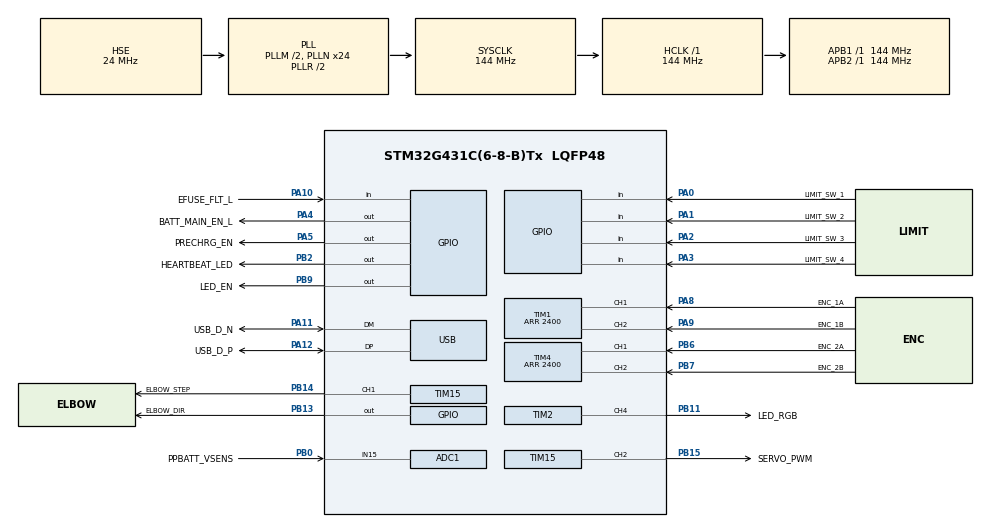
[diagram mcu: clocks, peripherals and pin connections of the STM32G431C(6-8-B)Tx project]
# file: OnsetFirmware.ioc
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ADC1.Channel-5\#ChannelRegularConversion=ADC_CHANNEL_15
ADC1.Channel-IN15=ADC_CHANNEL_15
ADC1.ClockPrescaler=ADC_CLOCK_SYNC_PCLK_DIV4
ADC1.ContinuousConvMode=DISABLE
ADC1.DMAContinuousRequests=DISABLE
ADC1.DataAlign=ADC_DATAALIGN_RIGHT
ADC1.DiscontinuousConvMode=DISABLE
ADC1.EOCSelection=ADC_EOC_SINGLE_CONV
ADC1.EnableAnalogWatchDog1=false
ADC1.EnableAnalogWatchDog2=false
ADC1.EnableAnalogWatchDog3=false
ADC1.EnableInjectedConversion=DISABLE
ADC1.EnableRegularConversion=ENABLE
ADC1.ExternalTrigConv=ADC_SOFTWARE_START
ADC1.ExternalTrigConvEdge=ADC_EXTERNALTRIGCONVEDGE_NONE
ADC1.GainCompensation=0
ADC1.LowPowerAutoWait=DISABLE
ADC1.Mode=ADC_MODE_INDEPENDENT
ADC1.NbrOfConversion=1
ADC1.OffsetNumber-5\#ChannelRegularConversion=ADC_OFFSET_NONE
ADC1.Overrun=ADC_OVR_DATA_PRESERVED
ADC1.OversamplingMode=DISABLE
ADC1.Rank-5\#ChannelRegularConversion=1
ADC1.Resolution=ADC_RESOLUTION_12B
ADC1.SamplingTime-5\#ChannelRegularConversion=ADC_SAMPLETIME_2CYCLES_5
ADC1.ScanConvMode=ADC_SCAN_DISABLE
ADC1.master=1
Dma.Request0=TIM2_CH4
Dma.TIM2_CH4.0.Direction=DMA_MEMORY_TO_PERIPH
Dma.TIM2_CH4.0.EventEnable=DISABLE
Dma.TIM2_CH4.0.Instance=DMA1_Channel1
Dma.TIM2_CH4.0.MemDataAlignment=DMA_MDATAALIGN_WORD
Dma.TIM2_CH4.0.MemInc=DMA_MINC_ENABLE
Dma.TIM2_CH4.0.Mode=DMA_NORMAL
Dma.TIM2_CH4.0.PeriphDataAlignment=DMA_PDATAALIGN_WORD
Dma.TIM2_CH4.0.PeriphInc=DMA_PINC_DISABLE
Dma.TIM2_CH4.0.Polarity=HAL_DMAMUX_REQ_GEN_RISING
Dma.TIM2_CH4.0.Priority=DMA_PRIORITY_LOW
Dma.TIM2_CH4.0.RequestNumber=1
Dma.TIM2_CH4.0.SignalID=NONE
Dma.TIM2_CH4.0.SyncEnable=DISABLE
Dma.TIM2_CH4.0.SyncPolarity=HAL_DMAMUX_SYNC_NO_EVENT
Dma.TIM2_CH4.0.SyncRequestNumber=1
Dma.TIM2_CH4.0.SyncSignalID=NONE
FREERTOS.HEAP_NUMBER=4
FREERTOS.INCLUDE_eTaskGetState=1
FREERTOS.INCLUDE_pcTaskGetTaskName=0
FREERTOS.INCLUDE_uxTaskGetStackHighWaterMark=1
FREERTOS.INCLUDE_uxTaskGetStackHighWaterMark2=0
FREERTOS.INCLUDE_uxTaskPriorityGet=1
FREERTOS.INCLUDE_vTaskCleanUpResources=0
FREERTOS.INCLUDE_vTaskDelay=1
FREERTOS.INCLUDE_vTaskDelayUntil=1
FREERTOS.INCLUDE_vTaskDelete=1
FREERTOS.INCLUDE_vTaskPrioritySet=1
FREERTOS.INCLUDE_vTaskSuspend=1
FREERTOS.INCLUDE_xEventGroupSetBitFromISR=0
FREERTOS.INCLUDE_xQueueGetMutexHolder=1
FREERTOS.INCLUDE_xSemaphoreGetMutexHolder=0
FREERTOS.INCLUDE_xTaskAbortDelay=0
FREERTOS.INCLUDE_xTaskGetCurrentTaskHandle=1
FREERTOS.INCLUDE_xTaskGetHandle=0
FREERTOS.INCLUDE_xTaskGetSchedulerState=1
FREERTOS.INCLUDE_xTaskResumeFromISR=1
FREERTOS.INCLUDE_xTimerPendFunctionCall=1
FREERTOS.Queues01=serial_to_elbow,16,serial_to_elbow_msg_t,0,Dynamic,NULL,NULL;elbow_to_serial,16,elbow_to_serial_msg_t,0,Dynamic,NULL,NULL;serial_to_precharge,16,serial_to_precharge_msg_t,0,Dynamic,NULL,NULL;precharge_to_serial,16,precharge_to_serial_msg_t,0,Dynamic,NULL,NULL;precharge_to_led,16,precharge_to_led_msg_t,0,Dynamic,NULL,NULL;serial_to_led,16,serial_to_led_msg_t,0,Dynamic,NULL,NULL;led_to_serial,16,led_to_serial_msg_t,0,Dynamic,NULL,NULL;serial_to_loader,16,serial_to_loader_msg_t,0,Dynamic,NULL,NULL;loader_to_serial,16,loader_to_serial_msg_t,0,Dynamic,NULL,NULL
FREERTOS.Tasks01=default_task,24,128,start_default_task,Default,NULL,Dynamic,NULL,NULL;elbow_service,24,256,start_elbow_service,As external,NULL,Dynamic,NULL,NULL;heartbeat_service,24,64,start_heartbeat_service,As external,NULL,Dynamic,NULL,NULL;serial_service,24,512,start_serial_service,As external,NULL,Dynamic,NULL,NULL;precharge_service,24,128,start_precharge_service,As external,NULL,Dynamic,NULL,NULL;led_service,24,128,start_led_service,As external,NULL,Dynamic,NULL,NULL;loader_servce,24,64,start_loader_service,As external,NULL,Dynamic,NULL,NULL
FREERTOS.configCHECK_FOR_STACK_OVERFLOW=0
FREERTOS.configENABLE_BACKWARD_COMPATIBILITY=1
FREERTOS.configENABLE_FPU=0
FREERTOS.configGENERATE_RUN_TIME_STATS=0
FREERTOS.configIDLE_SHOULD_YIELD=1
FREERTOS.configLIBRARY_LOWEST_INTERRUPT_PRIORITY=15
FREERTOS.configLIBRARY_MAX_SYSCALL_INTERRUPT_PRIORITY=5
FREERTOS.configMAX_CO_ROUTINE_PRIORITIES=2
FREERTOS.configMAX_TASK_NAME_LEN=32
FREERTOS.configMINIMAL_STACK_SIZE=64
FREERTOS.configQUEUE_REGISTRY_SIZE=8
FREERTOS.configRECORD_STACK_HIGH_ADDRESS=0
FREERTOS.configTICK_RATE_HZ=1000
FREERTOS.configTIMER_QUEUE_LENGTH=10
FREERTOS.configTIMER_TASK_PRIORITY=2
FREERTOS.configTIMER_TASK_STACK_DEPTH=256
FREERTOS.configTOTAL_HEAP_SIZE=8192
FREERTOS.configUSE_APPLICATION_TASK_TAG=0
FREERTOS.configUSE_COUNTING_SEMAPHORES=1
FREERTOS.configUSE_CO_ROUTINES=0
FREERTOS.configUSE_DAEMON_TASK_STARTUP_HOOK=0
FREERTOS.configUSE_IDLE_HOOK=0
FREERTOS.configUSE_MALLOC_FAILED_HOOK=0
FREERTOS.configUSE_MINI_LIST_ITEM=1
FREERTOS.configUSE_MUTEXES=1
FREERTOS.configUSE_NEWLIB_REENTRANT=0
FREERTOS.configUSE_OS2_EVENTFLAGS_FROM_ISR=1
FREERTOS.configUSE_OS2_MUTEX=1
FREERTOS.configUSE_OS2_THREAD_ENUMERATE=1
FREERTOS.configUSE_OS2_THREAD_FLAGS=1
FREERTOS.configUSE_OS2_THREAD_SUSPEND_RESUME=1
FREERTOS.configUSE_OS2_TIMER=1
FREERTOS.configUSE_POSIX_ERRNO=0
FREERTOS.configUSE_PREEMPTION=1
FREERTOS.configUSE_RECURSIVE_MUTEXES=1
FREERTOS.configUSE_SB_COMPLETED_CALLBACK=0
FREERTOS.configUSE_STATS_FORMATTING_FUNCTIONS=0
FREERTOS.configUSE_TASK_NOTIFICATIONS=1
FREERTOS.configUSE_TICKLESS_IDLE=0
FREERTOS.configUSE_TICK_HOOK=0
FREERTOS.configUSE_TRACE_FACILITY=1
FREERTOS.copyHeapFile=1
Mcu.Family=STM32G4
Mcu.Name=STM32G431C(6-8-B)Tx
Mcu.Package=LQFP48
NVIC.DMA1_Channel1_IRQn=true\:5\:0\:true\:false\:true\:true\:false\:true\:true
NVIC.PriorityGroup=NVIC_PRIORITYGROUP_4
NVIC.TIM1_BRK_TIM15_IRQn=true\:5\:0\:true\:false\:true\:true\:true\:true\:true
NVIC.TIM3_IRQn=true\:5\:0\:true\:false\:true\:true\:true\:true\:true
NVIC.TIM6_DAC_IRQn=true\:15\:0\:false\:false\:true\:false\:true\:true\:true
NVIC.TimeBase=TIM6_DAC_IRQn
NVIC.TimeBaseIP=TIM6
NVIC.USB_LP_IRQn=true\:5\:0\:true\:false\:true\:true\:true\:true\:true
PA0.GPIO_Label=LIMIT_SW_1
PA0.GPIO_PuPd=GPIO_PULLUP
PA0.Signal=GPIO_Input
PA1.GPIO_Label=LIMIT_SW_2
PA1.GPIO_PuPd=GPIO_PULLUP
PA1.Signal=GPIO_Input
PA10.GPIO_Label=EFUSE_FLT_L
PA10.Signal=GPIO_Input
PA11.GPIO_Label=USB_D_N
PA11.Mode=Device
PA11.Signal=USB_DM
PA12.GPIO_Label=USB_D_P
PA12.Mode=Device
PA12.Signal=USB_DP
PA13.GPIO_Label=DEBUG_SWDIO
PA13.Mode=Trace_Asynchronous_SW
PA13.Signal=SYS_JTMS-SWDIO
PA14.GPIO_Label=DEBUG_SWCLK
PA14.Mode=Trace_Asynchronous_SW
PA14.Signal=SYS_JTCK-SWCLK
PA2.GPIO_Label=LIMIT_SW_3
PA2.GPIO_PuPd=GPIO_PULLUP
PA2.Signal=GPIO_Input
PA3.GPIO_Label=LIMIT_SW_4
PA3.GPIO_PuPd=GPIO_PULLUP
PA3.Signal=GPIO_Input
PA4.GPIO_Label=BATT_MAIN_EN_L
PA4.PinState=GPIO_PIN_SET
PA4.Signal=GPIO_Output
PA5.GPIO_Label=PRECHRG_EN
PA5.PinState=GPIO_PIN_SET
PA5.Signal=GPIO_Output
PA8.GPIO_Label=ENC_1A
PA8.GPIO_PuPd=GPIO_PULLUP
PA8.Signal=S_TIM1_CH1
PA9.GPIO_Label=ENC_1B
PA9.GPIO_PuPd=GPIO_PULLUP
PA9.Signal=S_TIM1_CH2
PB0.GPIO_Label=PPBATT_VSENS
PB0.Mode=IN15-Single-Ended
PB0.Signal=ADC1_IN15
PB11.GPIO_Label=LED_RGB
PB11.Signal=S_TIM2_CH4
PB13.GPIO_Label=ELBOW_DIR
PB13.Signal=GPIO_Output
PB14.GPIO_Label=ELBOW_STEP
PB14.Signal=S_TIM15_CH1
PB15.GPIO_Label=SERVO_PWM
PB15.Signal=S_TIM15_CH2
PB2.GPIO_Label=HEARTBEAT_LED
PB2.Signal=GPIO_Output
PB3.GPIO_Label=DEBUG_SWO
PB3.Mode=Trace_Asynchronous_SW
PB3.Signal=SYS_JTDO-SWO
PB6.GPIO_Label=ENC_2A
PB6.GPIO_PuPd=GPIO_PULLUP
PB6.Signal=S_TIM4_CH1
PB7.GPIO_Label=ENC_2B
PB7.GPIO_PuPd=GPIO_PULLUP
PB7.Signal=S_TIM4_CH2
PB9.GPIO_Label=LED_EN
PB9.Signal=GPIO_Output
PF0-OSC_IN.Mode=HSE-External-Oscillator
PF0-OSC_IN.Signal=RCC_OSC_IN
PF1-OSC_OUT.Mode=HSE-External-Oscillator
PF1-OSC_OUT.Signal=RCC_OSC_OUT
ProjectManager.HeapSize=0x200
ProjectManager.StackSize=0x400
ProjectManager.TargetToolchain=CMake
RCC.ADC12Freq_Value=144000000
RCC.AHBFreq_Value=144000000
RCC.APB1Freq_Value=144000000
RCC.APB1TimFreq_Value=144000000
RCC.APB2Freq_Value=144000000
RCC.APB2TimFreq_Value=144000000
RCC.CortexFreq_Value=144000000
RCC.EXTERNAL_CLOCK_VALUE=12288000
RCC.FLatency=FLASH_LATENCY_4
RCC.HCLKFreq_Value=144000000
RCC.HSE_VALUE=24000000
RCC.HSI48_VALUE=48000000
RCC.HSI_VALUE=16000000
RCC.LSE_VALUE=32768
RCC.PLLM=RCC_PLLM_DIV2
RCC.PLLN=24
RCC.PLLQ=RCC_PLLQ_DIV6
RCC.PLLSourceVirtual=RCC_PLLSOURCE_HSE
RCC.SYSCLKFreq_VALUE=144000000
RCC.SYSCLKSource=RCC_SYSCLKSOURCE_PLLCLK
RCC.USBFreq_Value=48000000
RCC.VCOOutputFreq_Value=288000000
SH.S_TIM15_CH1.0=TIM15_CH1,Output Compare1 CH1
SH.S_TIM15_CH2.0=TIM15_CH2,PWM Generation2 CH2
SH.S_TIM1_CH1.0=TIM1_CH1,Encoder_Interface
SH.S_TIM1_CH2.0=TIM1_CH2,Encoder_Interface
SH.S_TIM2_CH4.0=TIM2_CH4,PWM Generation4 CH4
SH.S_TIM4_CH1.0=TIM4_CH1,Encoder_Interface
SH.S_TIM4_CH2.0=TIM4_CH2,Encoder_Interface
TIM1.EncoderMode=TIM_ENCODERMODE_TI12
TIM1.IC1Polarity=TIM_ICPOLARITY_RISING
TIM1.IC2Polarity=TIM_ICPOLARITY_RISING
TIM1.PeriodNoDither=2400
TIM15.Channel-Output\ Compare1\ CH1=TIM_CHANNEL_1
TIM15.Channel-PWM\ Generation2\ CH2=TIM_CHANNEL_2
TIM15.OCMode_1=TIM_OCMODE_TOGGLE
TIM15.Prescaler=43
TIM16.Channel=TIM_CHANNEL_1
TIM2.Channel-PWM\ Generation4\ CH4=TIM_CHANNEL_4
TIM2.PeriodNoDither=179
TIM2.Prescaler=0
TIM3.AutoReloadPreload=TIM_AUTORELOAD_PRELOAD_DISABLE
TIM3.ClockDivision=TIM_CLOCKDIVISION_DIV1
TIM3.CounterMode=TIM_COUNTERMODE_UP
TIM3.Dithering=Disable
TIM3.PeriodNoDither=65535
TIM3.Prescaler=144
TIM3.TIM_MasterOutputTrigger=TIM_TRGO_RESET
TIM3.TIM_MasterSlaveMode=TIM_MASTERSLAVEMODE_DISABLE
TIM4.EncoderMode=TIM_ENCODERMODE_TI12
TIM4.PeriodNoDither=2400
USB.DeviceSpeed=PCD_SPEED_FULL
USB.Sof_enable=DISABLE
USB.battery_charging_enable=DISABLE
USB.low_power_enable=DISABLE
USB.lpm_enable=DISABLE
USB.phy_itface=PCD_PHY_EMBEDDED
USB_DEVICE.APP_RX_DATA_SIZE=1024
USB_DEVICE.APP_TX_DATA_SIZE=1024
USB_DEVICE.CLASS_NAME_FS=CDC
USB_DEVICE.CONFIGURATION_STRING_CDC_FS=CDC Config
USB_DEVICE.INTERFACE_STRING_CDC_FS=CDC Interface
USB_DEVICE.LANGID_STRING=1033
USB_DEVICE.MANUFACTURER_STRING=Onset Team
USB_DEVICE.PID_CDC_FS=22336
USB_DEVICE.PRODUCT_STRING_CDC_FS=Onset Main Board
USB_DEVICE.USBD_DEBUG_LEVEL=0
USB_DEVICE.USBD_LPM_ENABLED=1
USB_DEVICE.USBD_MAX_NUM_CONFIGURATION=1
USB_DEVICE.USBD_MAX_NUM_INTERFACES=1
USB_DEVICE.USBD_MAX_STR_DESC_SIZ=512
USB_DEVICE.USBD_SELF_POWERED=1
USB_DEVICE.VID=1155
USB_DEVICE.VirtualMode=Cdc
USB_DEVICE.VirtualModeFS=Cdc_FS
VP_FREERTOS_VS_CMSIS_V2.Mode=CMSIS_V2
VP_SYS_VS_DBSignals.Mode=DisableDeadBatterySignals
VP_SYS_VS_tim6.Mode=TIM6
VP_TIM16_VS_ClockSourceINT.Mode=Enable_Timer
VP_TIM3_VS_ClockSourceINT.Mode=Internal
VP_USB_DEVICE_VS_USB_DEVICE_CDC_FS.Mode=CDC_FS
board=custom

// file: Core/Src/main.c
/* USER CODE BEGIN Header */
/**
  ******************************************************************************
  * @file           : main.c
  * @brief          : Main program body
  ******************************************************************************
  * @attention
  *
  * Copyright (c) 2026 STMicroelectronics.
  * All rights reserved.
  *
  * This software is licensed under terms that can be found in the LICENSE file
  * in the root directory of this software component.
  * If no LICENSE file comes with this software, it is provided AS-IS.
  *
  ******************************************************************************
  */
/* USER CODE END Header */
#include "main.h"
#include "cmsis_os.h"
#include "adc.h"
#include "dma.h"
#include "tim.h"
#include "usb_device.h"
#include "gpio.h"

void SystemClock_Config(void);
void MX_FREERTOS_Init(void);

int main(void)
{

  /* MCU Configuration--------------------------------------------------------*/

  /* Reset of all peripherals, Initializes the Flash interface and the Systick. */
  HAL_Init();

  /* Configure the system clock */
  SystemClock_Config();

  /* Initialize all configured peripherals */
  MX_GPIO_Init();
  MX_DMA_Init();
  MX_ADC1_Init();
  MX_TIM2_Init();
  MX_TIM3_Init();
  MX_TIM1_Init();
  MX_TIM4_Init();
  MX_TIM16_Init();
  MX_TIM15_Init();

  /* Init scheduler */
  osKernelInitialize();  /* Call init function for freertos objects (in cmsis_os2.c) */
  MX_FREERTOS_Init();

  /* Start scheduler */
  osKernelStart();

  /* We should never get here as control is now taken by the scheduler */

  /* Infinite loop */
  while (1)
  {

  }
}

void SystemClock_Config(void)
{
  RCC_OscInitTypeDef RCC_OscInitStruct = {0};
  RCC_ClkInitTypeDef RCC_ClkInitStruct = {0};

  /** Configure the main internal regulator output voltage
  */
  HAL_PWREx_ControlVoltageScaling(PWR_REGULATOR_VOLTAGE_SCALE1);

  /** Initializes the RCC Oscillators according to the specified parameters
  * in the RCC_OscInitTypeDef structure.
  */
  RCC_OscInitStruct.OscillatorType = RCC_OSCILLATORTYPE_HSE;
  RCC_OscInitStruct.HSEState = RCC_HSE_ON;
  RCC_OscInitStruct.PLL.PLLState = RCC_PLL_ON;
  RCC_OscInitStruct.PLL.PLLSource = RCC_PLLSOURCE_HSE;
  RCC_OscInitStruct.PLL.PLLM = RCC_PLLM_DIV2;
  RCC_OscInitStruct.PLL.PLLN = 24;
  RCC_OscInitStruct.PLL.PLLP = RCC_PLLP_DIV2;
  RCC_OscInitStruct.PLL.PLLQ = RCC_PLLQ_DIV6;
  RCC_OscInitStruct.PLL.PLLR = RCC_PLLR_DIV2;
  if (HAL_RCC_OscConfig(&RCC_OscInitStruct) != HAL_OK)
  {
    Error_Handler();
  }

  /** Initializes the CPU, AHB and APB buses clocks
  */
  RCC_ClkInitStruct.ClockType = RCC_CLOCKTYPE_HCLK|RCC_CLOCKTYPE_SYSCLK
                              |RCC_CLOCKTYPE_PCLK1|RCC_CLOCKTYPE_PCLK2;
  RCC_ClkInitStruct.SYSCLKSource = RCC_SYSCLKSOURCE_PLLCLK;
  RCC_ClkInitStruct.AHBCLKDivider = RCC_SYSCLK_DIV1;
  RCC_ClkInitStruct.APB1CLKDivider = RCC_HCLK_DIV1;
  RCC_ClkInitStruct.APB2CLKDivider = RCC_HCLK_DIV1;

  if (HAL_RCC_ClockConfig(&RCC_ClkInitStruct, FLASH_LATENCY_4) != HAL_OK)
  {
    Error_Handler();
  }
}

void HAL_TIM_PeriodElapsedCallback(TIM_HandleTypeDef *htim)
{
  if (htim->Instance == TIM6)
  {
    HAL_IncTick();
  }
}

void Error_Handler(void)
{
  __disable_irq();
  while (1)
  {
  }
}

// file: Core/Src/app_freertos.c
/* USER CODE BEGIN Header */
/**
  ******************************************************************************
  * File Name          : app_freertos.c
  * Description        : Code for freertos applications
  ******************************************************************************
  * @attention
  *
  * Copyright (c) 2026 STMicroelectronics.
  * All rights reserved.
  *
  * This software is licensed under terms that can be found in the LICENSE file
  * in the root directory of this software component.
  * If no LICENSE file comes with this software, it is provided AS-IS.
  *
  ******************************************************************************
  */
/* USER CODE END Header */

#include "FreeRTOS.h"
#include "task.h"
#include "main.h"
#include "cmsis_os.h"

#include "usb_device.h"

/* USER CODE BEGIN Includes */
#include "freertos_handles.h"
#include "heartbeat_service.h"
#include "elbow_service.h"
#include "serial_service.h"
#include "precharge_service.h"
#include "led_service.h"
#include "loader_service.h"
/* USER CODE END Includes */

/* Definitions for default_task */
osThreadId_t default_taskHandle;
const osThreadAttr_t default_task_attributes = {
  .name = "default_task",
  .priority = (osPriority_t) osPriorityNormal,
  .stack_size = 128 * 4
};
/* Definitions for elbow_service */
osThreadId_t elbow_serviceHandle;
const osThreadAttr_t elbow_service_attributes = {
  .name = "elbow_service",
  .priority = (osPriority_t) osPriorityNormal,
  .stack_size = 256 * 4
};
/* Definitions for heartbeat_service */
osThreadId_t heartbeat_serviceHandle;
const osThreadAttr_t heartbeat_service_attributes = {
  .name = "heartbeat_service",
  .priority = (osPriority_t) osPriorityNormal,
  .stack_size = 64 * 4
};
/* Definitions for serial_service */
osThreadId_t serial_serviceHandle;
const osThreadAttr_t serial_service_attributes = {
  .name = "serial_service",
  .priority = (osPriority_t) osPriorityNormal,
  .stack_size = 512 * 4
};
/* Definitions for precharge_service */
osThreadId_t precharge_serviceHandle;
const osThreadAttr_t precharge_service_attributes = {
  .name = "precharge_service",
  .priority = (osPriority_t) osPriorityNormal,
  .stack_size = 128 * 4
};
/* Definitions for led_service */
osThreadId_t led_serviceHandle;
const osThreadAttr_t led_service_attributes = {
  .name = "led_service",
  .priority = (osPriority_t) osPriorityNormal,
  .stack_size = 128 * 4
};
/* Definitions for loader_servce */
osThreadId_t loader_servceHandle;
const osThreadAttr_t loader_servce_attributes = {
  .name = "loader_servce",
  .priority = (osPriority_t) osPriorityNormal,
  .stack_size = 64 * 4
};
/* Definitions for serial_to_elbow */
osMessageQueueId_t serial_to_elbowHandle;
const osMessageQueueAttr_t serial_to_elbow_attributes = {
  .name = "serial_to_elbow"
};
/* Definitions for elbow_to_serial */
osMessageQueueId_t elbow_to_serialHandle;
const osMessageQueueAttr_t elbow_to_serial_attributes = {
  .name = "elbow_to_serial"
};
/* Definitions for serial_to_precharge */
osMessageQueueId_t serial_to_prechargeHandle;
const osMessageQueueAttr_t serial_to_precharge_attributes = {
  .name = "serial_to_precharge"
};
/* Definitions for precharge_to_serial */
osMessageQueueId_t precharge_to_serialHandle;
const osMessageQueueAttr_t precharge_to_serial_attributes = {
  .name = "precharge_to_serial"
};
/* Definitions for precharge_to_led */
osMessageQueueId_t precharge_to_ledHandle;
const osMessageQueueAttr_t precharge_to_led_attributes = {
  .name = "precharge_to_led"
};
/* Definitions for serial_to_led */
osMessageQueueId_t serial_to_ledHandle;
const osMessageQueueAttr_t serial_to_led_attributes = {
  .name = "serial_to_led"
};
/* Definitions for led_to_serial */
osMessageQueueId_t led_to_serialHandle;
const osMessageQueueAttr_t led_to_serial_attributes = {
  .name = "led_to_serial"
};
/* Definitions for serial_to_loader */
osMessageQueueId_t serial_to_loaderHandle;
const osMessageQueueAttr_t serial_to_loader_attributes = {
  .name = "serial_to_loader"
};
/* Definitions for loader_to_serial */
osMessageQueueId_t loader_to_serialHandle;
const osMessageQueueAttr_t loader_to_serial_attributes = {
  .name = "loader_to_serial"
};

void start_default_task(void *argument);
extern void start_elbow_service(void *argument);
extern void start_heartbeat_service(void *argument);
extern void start_serial_service(void *argument);
extern void start_precharge_service(void *argument);
extern void start_led_service(void *argument);
extern void start_loader_service(void *argument);

void MX_FREERTOS_Init(void); /* (MISRA C 2004 rule 8.1) */

void MX_FREERTOS_Init(void) {

  /* Create the queue(s) */
  /* creation of serial_to_elbow */
  serial_to_elbowHandle = osMessageQueueNew (16, sizeof(serial_to_elbow_msg_t), &serial_to_elbow_attributes);

  /* creation of elbow_to_serial */
  elbow_to_serialHandle = osMessageQueueNew (16, sizeof(elbow_to_serial_msg_t), &elbow_to_serial_attributes);

  /* creation of serial_to_precharge */
  serial_to_prechargeHandle = osMessageQueueNew (16, sizeof(serial_to_precharge_msg_t), &serial_to_precharge_attributes);

  /* creation of precharge_to_serial */
  precharge_to_serialHandle = osMessageQueueNew (16, sizeof(precharge_to_serial_msg_t), &precharge_to_serial_attributes);

  /* creation of precharge_to_led */
  precharge_to_ledHandle = osMessageQueueNew (16, sizeof(precharge_to_led_msg_t), &precharge_to_led_attributes);

  /* creation of serial_to_led */
  serial_to_ledHandle = osMessageQueueNew (16, sizeof(serial_to_led_msg_t), &serial_to_led_attributes);

  /* creation of led_to_serial */
  led_to_serialHandle = osMessageQueueNew (16, sizeof(led_to_serial_msg_t), &led_to_serial_attributes);

  /* creation of serial_to_loader */
  serial_to_loaderHandle = osMessageQueueNew (16, sizeof(serial_to_loader_msg_t), &serial_to_loader_attributes);

  /* creation of loader_to_serial */
  loader_to_serialHandle = osMessageQueueNew (16, sizeof(loader_to_serial_msg_t), &loader_to_serial_attributes);

  /* Create the thread(s) */
  /* creation of default_task */
  default_taskHandle = osThreadNew(start_default_task, NULL, &default_task_attributes);

  /* creation of elbow_service */
  elbow_serviceHandle = osThreadNew(start_elbow_service, NULL, &elbow_service_attributes);

  /* creation of heartbeat_service */
  heartbeat_serviceHandle = osThreadNew(start_heartbeat_service, NULL, &heartbeat_service_attributes);

  /* creation of serial_service */
  serial_serviceHandle = osThreadNew(start_serial_service, NULL, &serial_service_attributes);

  /* creation of precharge_service */
  precharge_serviceHandle = osThreadNew(start_precharge_service, NULL, &precharge_service_attributes);

  /* creation of led_service */
  led_serviceHandle = osThreadNew(start_led_service, NULL, &led_service_attributes);

  /* creation of loader_servce */
  loader_servceHandle = osThreadNew(start_loader_service, NULL, &loader_servce_attributes);

}

void start_default_task(void *argument)
{
  /* init code for USB_Device */
  MX_USB_Device_Init();
  for(;;)
  {
    osDelay(1);
  }
}
